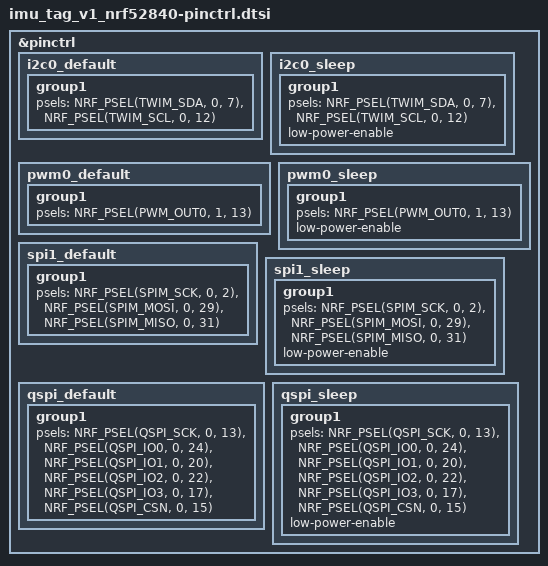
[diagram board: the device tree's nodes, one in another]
/*
 * Pin control definitions for IMU Tag v1 (E73-2G4M08S1C / nRF52840),
 * PCBA revision 1.1.0. Confirmed against the schematic and the Ebyte module
 * pin table.
 *
 * Pin map:
 *   SPI1  : SCK=P0.02  MOSI=P0.29  MISO=P0.31  CS(GPIO)=P0.05
 *   I2C0  : SDA=P0.07  SCL=P0.12
 *   QSPI  : SCK=P0.13  IO0=P0.24   IO1=P0.20   IO2=P0.22  IO3=P0.17  CSN=P0.15
 *   PWM0  : OUT0=P1.13 (status LED through R5)
 *   SAADC : AIN1=P0.03 (battery sense, analog input, not pin-muxed)
 *   UART0 : not wired on the PCB, no pinctrl states (&uart0 is disabled)
 *
 * Pins that are not pinctrl states: LSM6DSV16X INT1=P0.30, INT2=P0.08 (also
 * bonded to P1.09, the System OFF wake pin), GPIO_BAT_MEAS=P0.28. See the
 * board .dts for those.
 */

#include <dt-bindings/pinctrl/nrf-pinctrl.h>

&pinctrl {

	/* I2C0: LIS2MDL magnetometer. External 4.7 k pull-ups R16/R18 on the PCB. */
	i2c0_default: i2c0_default {
		group1 {
			psels = <NRF_PSEL(TWIM_SDA, 0, 7)>,    /* P0.07 */
			        <NRF_PSEL(TWIM_SCL, 0, 12)>;   /* P0.12 */
		};
	};
	i2c0_sleep: i2c0_sleep {
		group1 {
			psels = <NRF_PSEL(TWIM_SDA, 0, 7)>,
			        <NRF_PSEL(TWIM_SCL, 0, 12)>;
			low-power-enable;
		};
	};

	/* PWM0: status LED brightness control. */
	pwm0_default: pwm0_default {
		group1 {
			psels = <NRF_PSEL(PWM_OUT0, 1, 13)>;   /* P1.13 */
		};
	};
	pwm0_sleep: pwm0_sleep {
		group1 {
			psels = <NRF_PSEL(PWM_OUT0, 1, 13)>;
			low-power-enable;
		};
	};

	/* SPI1: LSM6DSV16X IMU. */
	spi1_default: spi1_default {
		group1 {
			psels = <NRF_PSEL(SPIM_SCK,  0, 2)>,   /* P0.02 */
			        <NRF_PSEL(SPIM_MOSI, 0, 29)>,  /* P0.29 */
			        <NRF_PSEL(SPIM_MISO, 0, 31)>;  /* P0.31 */
		};
	};
	spi1_sleep: spi1_sleep {
		group1 {
			psels = <NRF_PSEL(SPIM_SCK,  0, 2)>,
			        <NRF_PSEL(SPIM_MOSI, 0, 29)>,
			        <NRF_PSEL(SPIM_MISO, 0, 31)>;
			low-power-enable;
		};
	};

	/* QSPI: MX25R6435F NOR flash. */
	qspi_default: qspi_default {
		group1 {
			psels = <NRF_PSEL(QSPI_SCK, 0, 13)>,   /* P0.13 */
			        <NRF_PSEL(QSPI_IO0, 0, 24)>,    /* P0.24 */
			        <NRF_PSEL(QSPI_IO1, 0, 20)>,    /* P0.20 */
			        <NRF_PSEL(QSPI_IO2, 0, 22)>,    /* P0.22 */
			        <NRF_PSEL(QSPI_IO3, 0, 17)>,    /* P0.17 */
			        <NRF_PSEL(QSPI_CSN, 0, 15)>;    /* P0.15 */
		};
	};
	qspi_sleep: qspi_sleep {
		group1 {
			psels = <NRF_PSEL(QSPI_SCK, 0, 13)>,
			        <NRF_PSEL(QSPI_IO0, 0, 24)>,
			        <NRF_PSEL(QSPI_IO1, 0, 20)>,
			        <NRF_PSEL(QSPI_IO2, 0, 22)>,
			        <NRF_PSEL(QSPI_IO3, 0, 17)>,
			        <NRF_PSEL(QSPI_CSN, 0, 15)>;
			low-power-enable;
		};
	};
};
